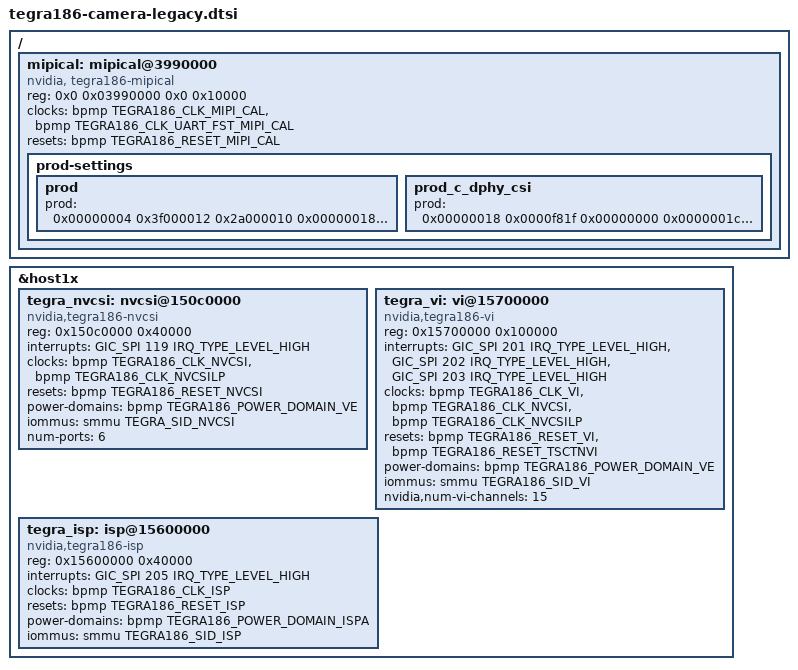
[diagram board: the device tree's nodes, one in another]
#include <dt-bindings/memory/tegra-swgroup.h>
/* Tegra186 legacy camera engines for NVIDIA downstream VI4/CSI4 stack. */

&host1x {
	tegra_nvcsi: nvcsi@150c0000 {
		compatible = "nvidia,tegra186-nvcsi";
		reg = <0x150c0000 0x40000>;
		interrupts = <GIC_SPI 119 IRQ_TYPE_LEVEL_HIGH>;
		clocks = <&bpmp TEGRA186_CLK_NVCSI>,
			 <&bpmp TEGRA186_CLK_NVCSILP>;
		clock-names = "nvcsi", "nvcsilp";
		resets = <&bpmp TEGRA186_RESET_NVCSI>;
		reset-names = "nvcsi";
		power-domains = <&bpmp TEGRA186_POWER_DOMAIN_VE>;
		iommus = <&smmu TEGRA_SID_NVCSI>;
		num-ports = <6>;
		status = "okay";
	};

	tegra_vi: vi@15700000 {
		compatible = "nvidia,tegra186-vi";
		reg = <0x15700000 0x100000>;
		interrupts = <GIC_SPI 201 IRQ_TYPE_LEVEL_HIGH>,
			     <GIC_SPI 202 IRQ_TYPE_LEVEL_HIGH>,
			     <GIC_SPI 203 IRQ_TYPE_LEVEL_HIGH>;
		clocks = <&bpmp TEGRA186_CLK_VI>,
			 <&bpmp TEGRA186_CLK_NVCSI>,
			 <&bpmp TEGRA186_CLK_NVCSILP>;
		clock-names = "vi", "nvcsi", "nvcsilp";
		resets = <&bpmp TEGRA186_RESET_VI>,
			 <&bpmp TEGRA186_RESET_TSCTNVI>;
		reset-names = "vi", "tsctnvi";
		power-domains = <&bpmp TEGRA186_POWER_DOMAIN_VE>;
		iommus = <&smmu TEGRA186_SID_VI>;
		nvidia,num-vi-channels = <15>;
		status = "okay";
	};

	tegra_isp: isp@15600000 {
		compatible = "nvidia,tegra186-isp";
		reg = <0x15600000 0x40000>;
		interrupts = <GIC_SPI 205 IRQ_TYPE_LEVEL_HIGH>;
		clocks = <&bpmp TEGRA186_CLK_ISP>;
		clock-names = "isp";
		resets = <&bpmp TEGRA186_RESET_ISP>;
		reset-names = "isp";
		power-domains = <&bpmp TEGRA186_POWER_DOMAIN_ISPA>;
		iommus = <&smmu TEGRA186_SID_ISP>;
		status = "okay";
	};
};

/ {
	mipical: mipical@3990000 {
		compatible = "nvidia, tegra186-mipical";
		reg = <0x0 0x03990000 0x0 0x10000>;
		clocks = <&bpmp TEGRA186_CLK_MIPI_CAL>,
			 <&bpmp TEGRA186_CLK_UART_FST_MIPI_CAL>;
		clock-names = "mipi_cal", "uart_fs_mipi_cal";
		resets = <&bpmp TEGRA186_RESET_MIPI_CAL>;
		reset-names = "mipi_cal";
		status = "okay";

		prod-settings {
			#prod-cells = <3>;
			prod {
				prod = <
					0x00000004 0x3f000012 0x2a000010
					0x00000018 0x40000000 0x00000000
					0x0000001c 0x40000000 0x00000000
					0x00000020 0x40000000 0x00000000
					0x00000024 0x40000000 0x00000000
					0x00000028 0x40000000 0x00000000
					0x0000002c 0x40000000 0x00000000
					0x0000003c 0x00001f00 0x00000200
					0x00000040 0x00001f00 0x00000200
					0x00000044 0x00001f00 0x00000200
					0x00000048 0x00001f00 0x00000200
					0x0000005c 0x00000001 0x00000000
					0x00000060 0x000f0f0f 0x00000000
					0x00000064 0x0f0ffff5 0x00010010
					0x00000068 0x4000001f 0x00000000
					0x0000006c 0x4000001f 0x00000000
					0x00000074 0x4000001f 0x00000000
					0x00000078 0x4000001f 0x00000000>;
			};
			prod_c_dphy_csi {
				prod = <
					0x00000018 0x0000f81f 0x00000000
					0x0000001c 0x0000f81f 0x00000000
					0x00000020 0x0000f81f 0x00000000
					0x00000024 0x0000f81f 0x00000000
					0x00000028 0x0000f81f 0x00000000
					0x0000002c 0x0000f81f 0x00000000>;
			};
		};
	};
};
